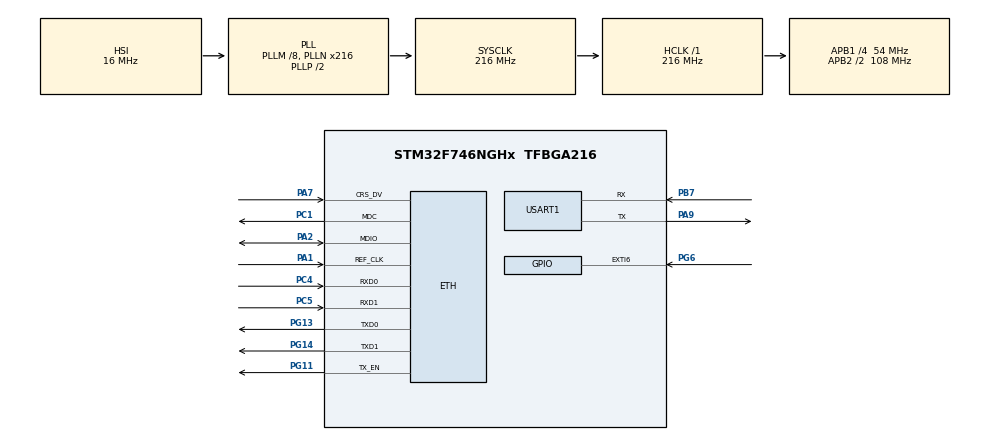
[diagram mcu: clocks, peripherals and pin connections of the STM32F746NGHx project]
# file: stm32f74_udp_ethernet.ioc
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Mcu.Family=STM32F7
RCC.CortexFreq_Value=216000000
PG6.Signal=GPXTI6
PA7.Mode=RMII
PC4.Signal=ETH_RXD0
ETH.MACAddr=00\:80\:E1\:B4\:C5\:02
LWIP.LWIP_DHCP=1
PC5.Mode=RMII
RCC.APB1CLKDivider=RCC_HCLK_DIV4
PG13.Signal=ETH_TXD0
ETH.PhyAddress=0
PG11.Signal=ETH_TX_EN
RCC.SYSCLKSource=RCC_SYSCLKSOURCE_PLLCLK
ProjectManager.StackSize=0x400
VP_LWIP_VS_Enabled.Mode=Enabled
RCC.PLLSAIRDiv=RCC_PLLSAIDIVR_8
LWIP.NETMASK_ADDRESS=255.255.255.000
USART1.VirtualMode-Asynchronous=VM_ASYNC
PA9.Mode=Asynchronous
ProjectManager.TargetToolchain=STM32CubeIDE
RCC.PLL48CLockSelection=RCC_CLK48SOURCE_PLLSAIP
RCC.HCLKFreq_Value=216000000
RCC.APB2TimFreq_Value=216000000
PA9.Signal=USART1_TX
RCC.USBFreq_Value=96000000
RCC.LSE_VALUE=32768
PA1.Signal=ETH_REF_CLK
RCC.AHBFreq_Value=216000000
PG14.Signal=ETH_TXD1
RCC.HSE_VALUE=25000000
board=STM32F746G-DISCO
RCC.VCOOutputFreq_Value=432000000
PG14.Mode=RMII
RCC.APB2Freq_Value=108000000
PA1.Mode=RMII
PG6.GPIO_ModeDefaultEXTI=GPIO_MODE_IT_FALLING
PB7.Signal=USART1_RX
PG13.Mode=RMII
Mcu.Name=STM32F746NGHx
PA2.Signal=ETH_MDIO
RCC.SYSCLKFreq_VALUE=216000000
Mcu.Package=TFBGA216
ETH.MediaInterface=ETH_MEDIA_INTERFACE_RMII
RCC.SDMMCClockSelection=RCC_SDMMC1CLKSOURCE_CLK48
PG11.Mode=RMII
PB7.Mode=Asynchronous
NVIC.EXTI9_5_IRQn=true\:0\:0\:false\:false\:true\:true\:true
ProjectManager.HeapSize=0x200
LWIP.Version=v2.1.2_Cube
RCC.HSI_VALUE=16000000
RCC.PLLSAIN=384
RCC.PLLSAIP=RCC_PLLSAIP_DIV8
RCC.PLLQ=9
NVIC.PriorityGroup=NVIC_PRIORITYGROUP_4
RCC.PLLSAIR=5
RCC.APB2CLKDivider=RCC_HCLK_DIV2
RCC.PLLM=8
RCC.PLLN=216
RCC.APB1TimFreq_Value=108000000
PA2.Mode=RMII
PC5.Signal=ETH_RXD1
RCC.APB1Freq_Value=54000000
RCC.PLLI2SN=100
PC1.Signal=ETH_MDC
PC4.Mode=RMII
LWIP.IP_ADDRESS=192.168.001.001
PC1.Mode=RMII
PA7.Signal=ETH_CRS_DV

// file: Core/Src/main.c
/* USER CODE BEGIN Header */
/**
  ******************************************************************************
  * @file           : main.c
  * @brief          : Main program body
  ******************************************************************************
  * @attention
  *
  * <h2><center>&copy; Copyright (c) 2021 STMicroelectronics.
  * All rights reserved.</center></h2>
  *
  * This software component is licensed by ST under Ultimate Liberty license
  * SLA0044, the "License"; You may not use this file except in compliance with
  * the License. You may obtain a copy of the License at:
  *                             www.st.com/SLA0044
  *
  ******************************************************************************
  */
/* USER CODE END Header */
#include "main.h"
#include "lwip.h"

/* USER CODE BEGIN Includes */
#include "custom_udp.h"
/* USER CODE END Includes */

UART_HandleTypeDef huart1;

void SystemClock_Config(void);
static void MX_GPIO_Init(void);
static void MX_USART1_UART_Init(void);

int main(void)
{

  /* MCU Configuration--------------------------------------------------------*/

  /* Reset of all peripherals, Initializes the Flash interface and the Systick. */
  HAL_Init();

  /* Configure the system clock */
  SystemClock_Config();

  /* Initialize all configured peripherals */
  MX_GPIO_Init();
  MX_USART1_UART_Init();
  MX_LWIP_Init();

  /* Infinite loop */
  while (1)
  {

  }
}

void SystemClock_Config(void)
{
  RCC_OscInitTypeDef RCC_OscInitStruct = {0};
  RCC_ClkInitTypeDef RCC_ClkInitStruct = {0};
  RCC_PeriphCLKInitTypeDef PeriphClkInitStruct = {0};

  /** Configure the main internal regulator output voltage
  */
  __HAL_RCC_PWR_CLK_ENABLE();
  __HAL_PWR_VOLTAGESCALING_CONFIG(PWR_REGULATOR_VOLTAGE_SCALE1);
  /** Initializes the RCC Oscillators according to the specified parameters
  * in the RCC_OscInitTypeDef structure.
  */
  RCC_OscInitStruct.OscillatorType = RCC_OSCILLATORTYPE_HSI;
  RCC_OscInitStruct.HSIState = RCC_HSI_ON;
  RCC_OscInitStruct.HSICalibrationValue = RCC_HSICALIBRATION_DEFAULT;
  RCC_OscInitStruct.PLL.PLLState = RCC_PLL_ON;
  RCC_OscInitStruct.PLL.PLLSource = RCC_PLLSOURCE_HSI;
  RCC_OscInitStruct.PLL.PLLM = 8;
  RCC_OscInitStruct.PLL.PLLN = 216;
  RCC_OscInitStruct.PLL.PLLP = RCC_PLLP_DIV2;
  RCC_OscInitStruct.PLL.PLLQ = 9;
  if (HAL_RCC_OscConfig(&RCC_OscInitStruct) != HAL_OK)
  {
    Error_Handler();
  }
  /** Activate the Over-Drive mode
  */
  if (HAL_PWREx_EnableOverDrive() != HAL_OK)
  {
    Error_Handler();
  }
  /** Initializes the CPU, AHB and APB buses clocks
  */
  RCC_ClkInitStruct.ClockType = RCC_CLOCKTYPE_HCLK|RCC_CLOCKTYPE_SYSCLK
                              |RCC_CLOCKTYPE_PCLK1|RCC_CLOCKTYPE_PCLK2;
  RCC_ClkInitStruct.SYSCLKSource = RCC_SYSCLKSOURCE_PLLCLK;
  RCC_ClkInitStruct.AHBCLKDivider = RCC_SYSCLK_DIV1;
  RCC_ClkInitStruct.APB1CLKDivider = RCC_HCLK_DIV4;
  RCC_ClkInitStruct.APB2CLKDivider = RCC_HCLK_DIV2;

  if (HAL_RCC_ClockConfig(&RCC_ClkInitStruct, FLASH_LATENCY_7) != HAL_OK)
  {
    Error_Handler();
  }
  PeriphClkInitStruct.PeriphClockSelection = RCC_PERIPHCLK_USART1;
  PeriphClkInitStruct.Usart1ClockSelection = RCC_USART1CLKSOURCE_PCLK2;
  if (HAL_RCCEx_PeriphCLKConfig(&PeriphClkInitStruct) != HAL_OK)
  {
    Error_Handler();
  }
}

static void MX_USART1_UART_Init(void)
{

  huart1.Instance = USART1;
  huart1.Init.BaudRate = 115200;
  huart1.Init.WordLength = UART_WORDLENGTH_8B;
  huart1.Init.StopBits = UART_STOPBITS_1;
  huart1.Init.Parity = UART_PARITY_NONE;
  huart1.Init.Mode = UART_MODE_TX_RX;
  huart1.Init.HwFlowCtl = UART_HWCONTROL_NONE;
  huart1.Init.OverSampling = UART_OVERSAMPLING_16;
  huart1.Init.OneBitSampling = UART_ONE_BIT_SAMPLE_DISABLE;
  huart1.AdvancedInit.AdvFeatureInit = UART_ADVFEATURE_NO_INIT;
  if (HAL_UART_Init(&huart1) != HAL_OK)
  {
    Error_Handler();
  }

}

static void MX_GPIO_Init(void)
{
  GPIO_InitTypeDef GPIO_InitStruct = {0};

  /* GPIO Ports Clock Enable */
  __HAL_RCC_GPIOG_CLK_ENABLE();
  __HAL_RCC_GPIOB_CLK_ENABLE();
  __HAL_RCC_GPIOA_CLK_ENABLE();
  __HAL_RCC_GPIOC_CLK_ENABLE();

  /*Configure GPIO pin : PG6 */
  GPIO_InitStruct.Pin = GPIO_PIN_6;
  GPIO_InitStruct.Mode = GPIO_MODE_IT_FALLING;
  GPIO_InitStruct.Pull = GPIO_NOPULL;
  HAL_GPIO_Init(GPIOG, &GPIO_InitStruct);

  /* EXTI interrupt init*/
  HAL_NVIC_SetPriority(EXTI9_5_IRQn, 0, 0);
  HAL_NVIC_EnableIRQ(EXTI9_5_IRQn);

}

void Error_Handler(void)
{
  __disable_irq();
  while (1)
  {
  }
}

/************************ (C) COPYRIGHT STMicroelectronics *****END OF FILE****/
